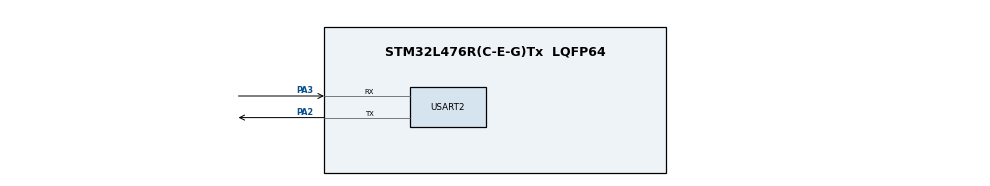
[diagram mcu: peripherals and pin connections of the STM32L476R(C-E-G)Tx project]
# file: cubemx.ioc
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Mcu.Family=STM32L4
Mcu.Name=STM32L476R(C-E-G)Tx
Mcu.Package=LQFP64
NVIC.PriorityGroup=NVIC_PRIORITYGROUP_4
PA13\ (JTMS-SWDIO).Mode=Serial_Wire
PA13\ (JTMS-SWDIO).Signal=SYS_JTMS-SWDIO
PA14\ (JTCK-SWCLK).Mode=Serial_Wire
PA14\ (JTCK-SWCLK).Signal=SYS_JTCK-SWCLK
PA2.Mode=Asynchronous
PA2.Signal=USART2_TX
PA3.Mode=Asynchronous
PA3.Signal=USART2_RX
PC14-OSC32_IN\ (PC14).Mode=LSE-External-Oscillator
PC14-OSC32_IN\ (PC14).Signal=RCC_OSC32_IN
PC15-OSC32_OUT\ (PC15).Mode=LSE-External-Oscillator
PC15-OSC32_OUT\ (PC15).Signal=RCC_OSC32_OUT
ProjectManager.HeapSize=0x200
ProjectManager.StackSize=0x400
ProjectManager.TargetToolchain=Makefile
RCC.HSE_VALUE=8000000
RCC.HSI_VALUE=16000000
RCC.MSI_VALUE=4000000
RCC.VCOOutputFreq_Value=32000000
USART2.VirtualMode-Asynchronous=VM_ASYNC
board=custom

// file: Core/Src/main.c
/* USER CODE BEGIN Header */
/**
  ******************************************************************************
  * @file           : main.c
  * @brief          : Main program body
  ******************************************************************************
  * @attention
  *
  * <h2><center>&copy; Copyright (c) 2020 STMicroelectronics.
  * All rights reserved.</center></h2>
  *
  * This software component is licensed by ST under BSD 3-Clause license,
  * the "License"; You may not use this file except in compliance with the
  * License. You may obtain a copy of the License at:
  *                        opensource.org/licenses/BSD-3-Clause
  *
  ******************************************************************************
  */
/* USER CODE END Header */

#include "main.h"

/* USER CODE BEGIN Includes */
#include "main_wrapper.h"
/* USER CODE END Includes */

UART_HandleTypeDef huart2;

void SystemClock_Config(void);
static void MX_GPIO_Init(void);
static void MX_USART2_UART_Init(void);

/* USER CODE BEGIN 0 */
static Context context = {
    .system_clock_config = SystemClock_Config,
    .gpio_init = MX_GPIO_Init,
    .console = { &huart2, MX_USART2_UART_Init },
    .uart_instances = {
        { NULL   , NULL },
        { &huart2, MX_USART2_UART_Init },
        { NULL   , NULL },
        { NULL   , NULL },
        { NULL   , NULL }
    },
    .i2c_instances = {
        {NULL, NULL},
        {NULL, NULL},
        {NULL, NULL}
    }
};
/* USER CODE END 0 */

int main(void)
{
  /* USER CODE BEGIN 1 */
  return main_wrapper(&context);
  /* USER CODE END 1 */

  /* MCU Configuration--------------------------------------------------------*/

  /* Reset of all peripherals, Initializes the Flash interface and the Systick. */
  HAL_Init();

  /* Configure the system clock */
  SystemClock_Config();

  /* Initialize all configured peripherals */
  MX_GPIO_Init();
  MX_USART2_UART_Init();

  /* Infinite loop */
  while (1)
  {

  }
}

void SystemClock_Config(void)
{
  RCC_OscInitTypeDef RCC_OscInitStruct = {0};
  RCC_ClkInitTypeDef RCC_ClkInitStruct = {0};
  RCC_PeriphCLKInitTypeDef PeriphClkInit = {0};

  /** Configure LSE Drive Capability
  */
  HAL_PWR_EnableBkUpAccess();
  __HAL_RCC_LSEDRIVE_CONFIG(RCC_LSEDRIVE_LOW);
  /** Initializes the CPU, AHB and APB busses clocks
  */
  RCC_OscInitStruct.OscillatorType = RCC_OSCILLATORTYPE_LSE|RCC_OSCILLATORTYPE_MSI;
  RCC_OscInitStruct.LSEState = RCC_LSE_ON;
  RCC_OscInitStruct.MSIState = RCC_MSI_ON;
  RCC_OscInitStruct.MSICalibrationValue = 0;
  RCC_OscInitStruct.MSIClockRange = RCC_MSIRANGE_6;
  RCC_OscInitStruct.PLL.PLLState = RCC_PLL_NONE;
  if (HAL_RCC_OscConfig(&RCC_OscInitStruct) != HAL_OK)
  {
    Error_Handler();
  }
  /** Initializes the CPU, AHB and APB busses clocks
  */
  RCC_ClkInitStruct.ClockType = RCC_CLOCKTYPE_HCLK|RCC_CLOCKTYPE_SYSCLK
                              |RCC_CLOCKTYPE_PCLK1|RCC_CLOCKTYPE_PCLK2;
  RCC_ClkInitStruct.SYSCLKSource = RCC_SYSCLKSOURCE_MSI;
  RCC_ClkInitStruct.AHBCLKDivider = RCC_SYSCLK_DIV1;
  RCC_ClkInitStruct.APB1CLKDivider = RCC_HCLK_DIV1;
  RCC_ClkInitStruct.APB2CLKDivider = RCC_HCLK_DIV1;

  if (HAL_RCC_ClockConfig(&RCC_ClkInitStruct, FLASH_LATENCY_0) != HAL_OK)
  {
    Error_Handler();
  }
  PeriphClkInit.PeriphClockSelection = RCC_PERIPHCLK_USART2;
  PeriphClkInit.Usart2ClockSelection = RCC_USART2CLKSOURCE_PCLK1;
  if (HAL_RCCEx_PeriphCLKConfig(&PeriphClkInit) != HAL_OK)
  {
    Error_Handler();
  }
  /** Configure the main internal regulator output voltage
  */
  if (HAL_PWREx_ControlVoltageScaling(PWR_REGULATOR_VOLTAGE_SCALE1) != HAL_OK)
  {
    Error_Handler();
  }
  /** Enable MSI Auto calibration
  */
  HAL_RCCEx_EnableMSIPLLMode();
}

static void MX_USART2_UART_Init(void)
{

  huart2.Instance = USART2;
  huart2.Init.BaudRate = 115200;
  huart2.Init.WordLength = UART_WORDLENGTH_8B;
  huart2.Init.StopBits = UART_STOPBITS_1;
  huart2.Init.Parity = UART_PARITY_NONE;
  huart2.Init.Mode = UART_MODE_TX_RX;
  huart2.Init.HwFlowCtl = UART_HWCONTROL_NONE;
  huart2.Init.OverSampling = UART_OVERSAMPLING_16;
  huart2.Init.OneBitSampling = UART_ONE_BIT_SAMPLE_DISABLE;
  huart2.AdvancedInit.AdvFeatureInit = UART_ADVFEATURE_NO_INIT;
  if (HAL_UART_Init(&huart2) != HAL_OK)
  {
    Error_Handler();
  }

}

static void MX_GPIO_Init(void)
{

  /* GPIO Ports Clock Enable */
  __HAL_RCC_GPIOC_CLK_ENABLE();
  __HAL_RCC_GPIOA_CLK_ENABLE();

}

void Error_Handler(void)
{
}

/************************ (C) COPYRIGHT STMicroelectronics *****END OF FILE****/
